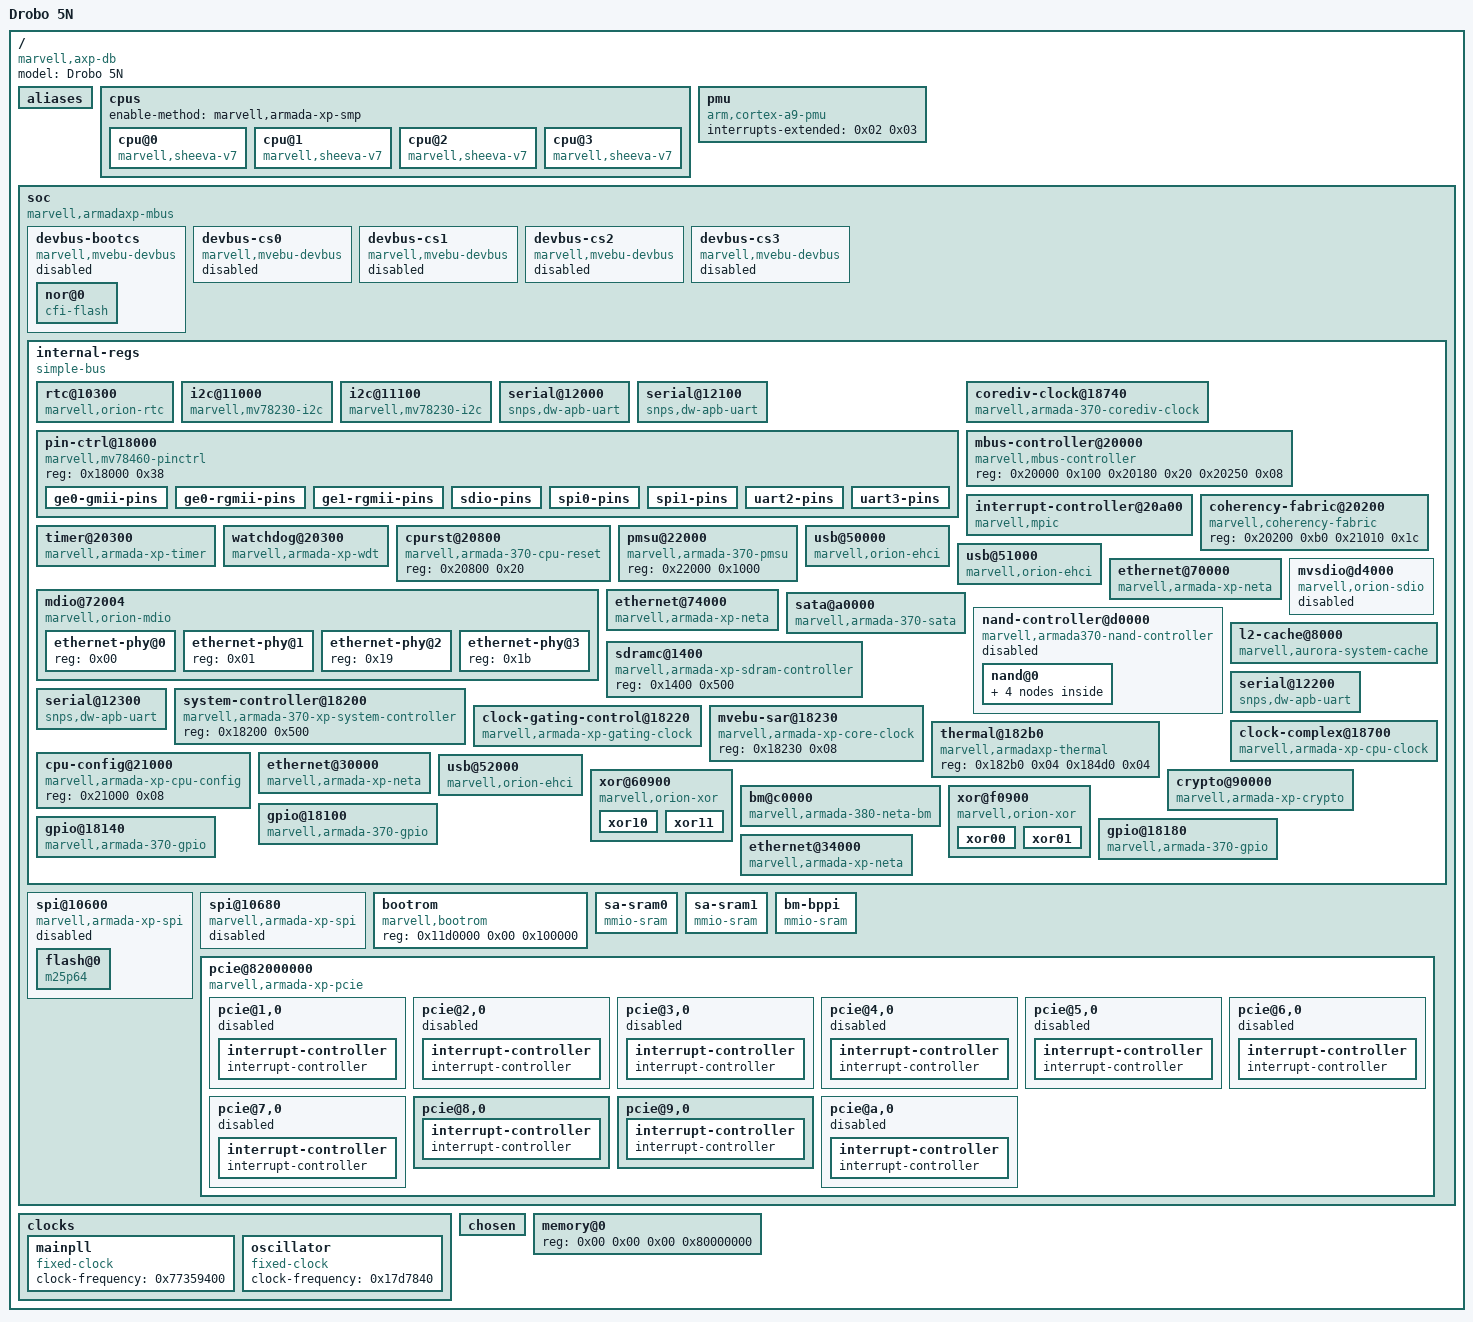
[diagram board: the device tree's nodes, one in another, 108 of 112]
/* Drobo 5N base device tree: mainline armada-xp-db with the register window at 0xd0000000,
   flash/SD/NAND off, only PCIe 8,0 and 9,0 on, both I2C buses on at 100 kHz.
   drobo5n-fixups.dtsi is applied on top by mkdrobodtb. */
/dts-v1/;

/ {
	model = "Drobo 5N";
	compatible = "marvell,axp-db", "marvell,armadaxp-mv78460", "marvell,armadaxp", "marvell,armada-370-xp";
	#address-cells = <0x02>;
	#size-cells = <0x02>;

	aliases {
		serial0 = "/soc/internal-regs/serial@12000";
		serial1 = "/soc/internal-regs/serial@12100";
		serial2 = "/soc/internal-regs/serial@12200";
		serial3 = "/soc/internal-regs/serial@12300";
		gpio0 = "/soc/internal-regs/gpio@18100";
		gpio1 = "/soc/internal-regs/gpio@18140";
		gpio2 = "/soc/internal-regs/gpio@18180";
	};

	cpus {
		#address-cells = <0x01>;
		#size-cells = <0x00>;
		enable-method = "marvell,armada-xp-smp";

		cpu@0 {
			compatible = "marvell,sheeva-v7";
			device_type = "cpu";
			reg = <0x00>;
			clocks = <0x01 0x00>;
			clock-latency = <0xf4240>;
		};

		cpu@1 {
			device_type = "cpu";
			compatible = "marvell,sheeva-v7";
			reg = <0x01>;
			clocks = <0x01 0x01>;
			clock-latency = <0xf4240>;
		};

		cpu@2 {
			device_type = "cpu";
			compatible = "marvell,sheeva-v7";
			reg = <0x02>;
			clocks = <0x01 0x02>;
			clock-latency = <0xf4240>;
		};

		cpu@3 {
			device_type = "cpu";
			compatible = "marvell,sheeva-v7";
			reg = <0x03>;
			clocks = <0x01 0x03>;
			clock-latency = <0xf4240>;
		};
	};

	pmu {
		compatible = "arm,cortex-a9-pmu";
		interrupts-extended = <0x02 0x03>;
	};

	soc {
		#address-cells = <0x02>;
		#size-cells = <0x01>;
		controller = <0x03>;
		interrupt-parent = <0x02>;
		pcie-mem-aperture = <0xf8000000 0x7e00000>;
		pcie-io-aperture = <0xffe00000 0x100000>;
		compatible = "marvell,armadaxp-mbus", "simple-bus";
		ranges = <0xf0010000 0x00 0x00 0xd0000000 0x100000 0x11d0000 0x00 0x00 0xfff00000 0x100000 0x12f0000 0x00 0x00 0xf0000000 0x1000000 0x9090000 0x00 0x00 0xf1100000 0x10000 0x9050000 0x00 0x00 0xf1110000 0x10000 0xc040000 0x00 0x00 0xf1200000 0x100000>;

		devbus-bootcs {
			compatible = "marvell,mvebu-devbus";
			reg = <0xf0010000 0x10400 0x08>;
			ranges = <0x00 0x12f0000 0x00 0xffffffff>;
			#address-cells = <0x01>;
			#size-cells = <0x01>;
			clocks = <0x04 0x00>;
			status = "disabled";
			devbus,bus-width = <0x10>;
			devbus,turn-off-ps = <0xea60>;
			devbus,badr-skew-ps = <0x00>;
			devbus,acc-first-ps = <0x1e460>;
			devbus,acc-next-ps = <0x3c8c0>;
			devbus,rd-setup-ps = <0x00>;
			devbus,rd-hold-ps = <0x00>;
			devbus,sync-enable = <0x00>;
			devbus,wr-high-ps = <0xea60>;
			devbus,wr-low-ps = <0xea60>;
			devbus,ale-wr-ps = <0xea60>;

			nor@0 {
				compatible = "cfi-flash";
				reg = <0x00 0x1000000>;
				bank-width = <0x02>;
			};
		};

		devbus-cs0 {
			compatible = "marvell,mvebu-devbus";
			reg = <0xf0010000 0x10408 0x08>;
			ranges = <0x00 0x13e0000 0x00 0xffffffff>;
			#address-cells = <0x01>;
			#size-cells = <0x01>;
			clocks = <0x04 0x00>;
			status = "disabled";
		};

		devbus-cs1 {
			compatible = "marvell,mvebu-devbus";
			reg = <0xf0010000 0x10410 0x08>;
			ranges = <0x00 0x13d0000 0x00 0xffffffff>;
			#address-cells = <0x01>;
			#size-cells = <0x01>;
			clocks = <0x04 0x00>;
			status = "disabled";
		};

		devbus-cs2 {
			compatible = "marvell,mvebu-devbus";
			reg = <0xf0010000 0x10418 0x08>;
			ranges = <0x00 0x13b0000 0x00 0xffffffff>;
			#address-cells = <0x01>;
			#size-cells = <0x01>;
			clocks = <0x04 0x00>;
			status = "disabled";
		};

		devbus-cs3 {
			compatible = "marvell,mvebu-devbus";
			reg = <0xf0010000 0x10420 0x08>;
			ranges = <0x00 0x1370000 0x00 0xffffffff>;
			#address-cells = <0x01>;
			#size-cells = <0x01>;
			clocks = <0x04 0x00>;
			status = "disabled";
		};

		internal-regs {
			compatible = "simple-bus";
			#address-cells = <0x01>;
			#size-cells = <0x01>;
			ranges = <0x00 0xf0010000 0x00 0x100000>;

			rtc@10300 {
				compatible = "marvell,orion-rtc";
				reg = <0x10300 0x20>;
				interrupts = <0x32>;
			};

			i2c@11000 {
				compatible = "marvell,mv78230-i2c", "marvell,mv64xxx-i2c";
				#address-cells = <0x01>;
				#size-cells = <0x00>;
				interrupts = <0x1f>;
				clocks = <0x04 0x00>;
				status = "okay";
				clock-frequency = <100000>;
				reg = <0x11000 0x100>;
			};

			i2c@11100 {
				compatible = "marvell,mv78230-i2c", "marvell,mv64xxx-i2c";
				#address-cells = <0x01>;
				#size-cells = <0x00>;
				interrupts = <0x20>;
				clocks = <0x04 0x00>;
				status = "okay";
				clock-frequency = <100000>;
				reg = <0x11100 0x100>;
			};

			serial@12000 {
				compatible = "snps,dw-apb-uart";
				reg = <0x12000 0x100>;
				reg-shift = <0x02>;
				interrupts = <0x29>;
				reg-io-width = <0x01>;
				clocks = <0x04 0x00>;
				status = "okay";
			};

			serial@12100 {
				compatible = "snps,dw-apb-uart";
				reg = <0x12100 0x100>;
				reg-shift = <0x02>;
				interrupts = <0x2a>;
				reg-io-width = <0x01>;
				clocks = <0x04 0x00>;
				status = "okay";
			};

			pin-ctrl@18000 {
				reg = <0x18000 0x38>;
				compatible = "marvell,mv78460-pinctrl";

				ge0-gmii-pins {
					marvell,pins = "mpp0", "mpp1", "mpp2", "mpp3", "mpp4", "mpp5", "mpp6", "mpp7", "mpp8", "mpp9", "mpp10", "mpp11", "mpp12", "mpp13", "mpp14", "mpp15", "mpp16", "mpp17", "mpp18", "mpp19", "mpp20", "mpp21", "mpp22", "mpp23";
					marvell,function = "ge0";
				};

				ge0-rgmii-pins {
					marvell,pins = "mpp0", "mpp1", "mpp2", "mpp3", "mpp4", "mpp5", "mpp6", "mpp7", "mpp8", "mpp9", "mpp10", "mpp11";
					marvell,function = "ge0";
				};

				ge1-rgmii-pins {
					marvell,pins = "mpp12", "mpp13", "mpp14", "mpp15", "mpp16", "mpp17", "mpp18", "mpp19", "mpp20", "mpp21", "mpp22", "mpp23";
					marvell,function = "ge1";
				};

				sdio-pins {
					marvell,pins = "mpp30", "mpp31", "mpp32", "mpp33", "mpp34", "mpp35";
					marvell,function = "sd0";
					phandle = <0x0c>;
				};

				spi0-pins {
					marvell,pins = "mpp36", "mpp37", "mpp38", "mpp39";
					marvell,function = "spi0";
					phandle = <0x14>;
				};

				spi1-pins {
					marvell,pins = "mpp13", "mpp14", "mpp16", "mpp17";
					marvell,function = "spi1";
					phandle = <0x15>;
				};

				uart2-pins {
					marvell,pins = "mpp42", "mpp43";
					marvell,function = "uart2";
					phandle = <0x0d>;
				};

				uart3-pins {
					marvell,pins = "mpp44", "mpp45";
					marvell,function = "uart3";
					phandle = <0x0e>;
				};
			};

			corediv-clock@18740 {
				compatible = "marvell,armada-370-corediv-clock";
				reg = <0x18740 0x0c>;
				#clock-cells = <0x01>;
				clocks = <0x05>;
				clock-output-names = "nand";
				phandle = <0x0b>;
			};

			mbus-controller@20000 {
				compatible = "marvell,mbus-controller";
				reg = <0x20000 0x100 0x20180 0x20 0x20250 0x08>;
				phandle = <0x03>;
			};

			interrupt-controller@20a00 {
				compatible = "marvell,mpic";
				#interrupt-cells = <0x01>;
				interrupt-controller;
				msi-controller;
				reg = <0x20a00 0x2d0 0x21070 0x58>;
				phandle = <0x02>;
			};

			coherency-fabric@20200 {
				compatible = "marvell,coherency-fabric";
				reg = <0x20200 0xb0 0x21010 0x1c>;
			};

			timer@20300 {
				reg = <0x20300 0x30 0x21040 0x30>;
				interrupts = <0x25 0x26 0x27 0x28 0x05 0x06>;
				compatible = "marvell,armada-xp-timer";
				clocks = <0x04 0x02 0x06>;
				clock-names = "nbclk", "fixed";
			};

			watchdog@20300 {
				reg = <0x20300 0x34 0x20704 0x04>;
				compatible = "marvell,armada-xp-wdt";
				clocks = <0x04 0x02 0x06>;
				clock-names = "nbclk", "fixed";
				interrupts = <0x5d 0x26>;
			};

			cpurst@20800 {
				compatible = "marvell,armada-370-cpu-reset";
				reg = <0x20800 0x20>;
			};

			pmsu@22000 {
				compatible = "marvell,armada-370-pmsu";
				reg = <0x22000 0x1000>;
			};

			usb@50000 {
				compatible = "marvell,orion-ehci";
				reg = <0x50000 0x500>;
				interrupts = <0x2d>;
				status = "okay";
				clocks = <0x07 0x12>;
			};

			usb@51000 {
				compatible = "marvell,orion-ehci";
				reg = <0x51000 0x500>;
				interrupts = <0x2e>;
				status = "okay";
				clocks = <0x07 0x13>;
			};

			ethernet@70000 {
				/* Put your board's MAC here (from U-Boot: printenv ethaddr) so DHCP gives a stable address:
				   local-mac-address = [00 1a 62 xx xx xx]; */
				reg = <0x70000 0x4000>;
				interrupts = <0x08>;
				clocks = <0x07 0x04>;
				status = "okay";
				compatible = "marvell,armada-xp-neta";
				phy = <0x08>;
				phy-mode = "rgmii-id";
				buffer-manager = <0x09>;
				bm,pool-long = <0x00>;
			};

			mdio@72004 {
				#address-cells = <0x01>;
				#size-cells = <0x00>;
				compatible = "marvell,orion-mdio";
				reg = <0x72004 0x04>;
				clocks = <0x07 0x04>;

				ethernet-phy@0 {
					reg = <0x00>;
					phandle = <0x08>;
				};

				ethernet-phy@1 {
					reg = <0x01>;
					phandle = <0x0a>;
				};

				ethernet-phy@2 {
					reg = <0x19>;
					phandle = <0x0f>;
				};

				ethernet-phy@3 {
					reg = <0x1b>;
					phandle = <0x13>;
				};
			};

			ethernet@74000 {
				reg = <0x74000 0x4000>;
				interrupts = <0x0a>;
				clocks = <0x07 0x03>;
				status = "okay";
				compatible = "marvell,armada-xp-neta";
				phy = <0x0a>;
				phy-mode = "rgmii-id";
				buffer-manager = <0x09>;
				bm,pool-long = <0x01>;
			};

			sata@a0000 {
				compatible = "marvell,armada-370-sata";
				reg = <0xa0000 0x5000>;
				interrupts = <0x37>;
				clocks = <0x07 0x0f 0x07 0x1e>;
				clock-names = "0", "1";
				status = "okay";
				nr-ports = <0x02>;
			};

			nand-controller@d0000 {
				compatible = "marvell,armada370-nand-controller";
				reg = <0xd0000 0x54>;
				#address-cells = <0x01>;
				#size-cells = <0x00>;
				interrupts = <0x71>;
				clocks = <0x0b 0x00>;
				status = "disabled";

				nand@0 {
					reg = <0x00>;
					label = "pxa3xx_nand-0";
					nand-rb = <0x00>;
					nand-on-flash-bbt;

					partitions {
						compatible = "fixed-partitions";
						#address-cells = <0x01>;
						#size-cells = <0x01>;

						partition@0 {
							label = "U-Boot";
							reg = <0x00 0x800000>;
						};

						partition@800000 {
							label = "Linux";
							reg = <0x800000 0x800000>;
						};

						partition@1000000 {
							label = "Filesystem";
							reg = <0x1000000 0x3f000000>;
						};
					};
				};
			};

			mvsdio@d4000 {
				compatible = "marvell,orion-sdio";
				reg = <0xd4000 0x200>;
				interrupts = <0x36>;
				clocks = <0x07 0x11>;
				bus-width = <0x04>;
				cap-sdio-irq;
				cap-sd-highspeed;
				cap-mmc-highspeed;
				status = "disabled";
				pinctrl-0 = <0x0c>;
				pinctrl-names = "default";
				broken-cd;
			};

			sdramc@1400 {
				compatible = "marvell,armada-xp-sdram-controller";
				reg = <0x1400 0x500>;
			};

			l2-cache@8000 {
				compatible = "marvell,aurora-system-cache";
				reg = <0x8000 0x1000>;
				cache-id-part = <0x100>;
				cache-level = <0x02>;
				cache-unified;
				wt-override;
			};

			serial@12200 {
				compatible = "snps,dw-apb-uart";
				pinctrl-0 = <0x0d>;
				pinctrl-names = "default";
				reg = <0x12200 0x100>;
				reg-shift = <0x02>;
				interrupts = <0x2b>;
				reg-io-width = <0x01>;
				clocks = <0x04 0x00>;
				status = "okay";
			};

			serial@12300 {
				compatible = "snps,dw-apb-uart";
				pinctrl-0 = <0x0e>;
				pinctrl-names = "default";
				reg = <0x12300 0x100>;
				reg-shift = <0x02>;
				interrupts = <0x2c>;
				reg-io-width = <0x01>;
				clocks = <0x04 0x00>;
				status = "okay";
			};

			system-controller@18200 {
				compatible = "marvell,armada-370-xp-system-controller";
				reg = <0x18200 0x500>;
			};

			clock-gating-control@18220 {
				compatible = "marvell,armada-xp-gating-clock";
				reg = <0x18220 0x04>;
				clocks = <0x04 0x00>;
				#clock-cells = <0x01>;
				phandle = <0x07>;
			};

			mvebu-sar@18230 {
				compatible = "marvell,armada-xp-core-clock";
				reg = <0x18230 0x08>;
				#clock-cells = <0x01>;
				phandle = <0x04>;
			};

			thermal@182b0 {
				compatible = "marvell,armadaxp-thermal";
				reg = <0x182b0 0x04 0x184d0 0x04>;
				status = "okay";
			};

			clock-complex@18700 {
				#clock-cells = <0x01>;
				compatible = "marvell,armada-xp-cpu-clock";
				reg = <0x18700 0x24 0x1c054 0x10>;
				clocks = <0x04 0x01>;
				phandle = <0x01>;
			};

			cpu-config@21000 {
				compatible = "marvell,armada-xp-cpu-config";
				reg = <0x21000 0x08>;
			};

			ethernet@30000 {
				compatible = "marvell,armada-xp-neta";
				reg = <0x30000 0x4000>;
				interrupts = <0x0c>;
				clocks = <0x07 0x02>;
				status = "okay";
				phy = <0x0f>;
				phy-mode = "sgmii";
				buffer-manager = <0x09>;
				bm,pool-long = <0x02>;
			};

			usb@52000 {
				compatible = "marvell,orion-ehci";
				reg = <0x52000 0x500>;
				interrupts = <0x2f>;
				clocks = <0x07 0x14>;
				status = "okay";
			};

			xor@60900 {
				compatible = "marvell,orion-xor";
				reg = <0x60900 0x100 0x60b00 0x100>;
				clocks = <0x07 0x16>;
				status = "okay";

				xor10 {
					interrupts = <0x33>;
					dmacap,memcpy;
					dmacap,xor;
				};

				xor11 {
					interrupts = <0x34>;
					dmacap,memcpy;
					dmacap,xor;
					dmacap,memset;
				};
			};

			crypto@90000 {
				compatible = "marvell,armada-xp-crypto";
				reg = <0x90000 0x10000>;
				reg-names = "regs";
				interrupts = <0x30 0x31>;
				clocks = <0x07 0x17 0x07 0x17>;
				clock-names = "cesa0", "cesa1";
				marvell,crypto-srams = <0x10 0x11>;
				marvell,crypto-sram-size = <0x800>;
			};

			bm@c0000 {
				compatible = "marvell,armada-380-neta-bm";
				reg = <0xc0000 0xac>;
				clocks = <0x07 0x0d>;
				internal-mem = <0x12>;
				status = "okay";
				phandle = <0x09>;
			};

			xor@f0900 {
				compatible = "marvell,orion-xor";
				reg = <0xf0900 0x100 0xf0b00 0x100>;
				clocks = <0x07 0x1c>;
				status = "okay";

				xor00 {
					interrupts = <0x5e>;
					dmacap,memcpy;
					dmacap,xor;
				};

				xor01 {
					interrupts = <0x5f>;
					dmacap,memcpy;
					dmacap,xor;
					dmacap,memset;
				};
			};

			gpio@18100 {
				compatible = "marvell,armada-370-gpio", "marvell,orion-gpio";
				reg = <0x18100 0x40 0x181c0 0x08>;
				reg-names = "gpio", "pwm";
				ngpios = <0x20>;
				gpio-controller;
				#gpio-cells = <0x02>;
				#pwm-cells = <0x02>;
				interrupt-controller;
				#interrupt-cells = <0x02>;
				interrupts = <0x52 0x53 0x54 0x55>;
				clocks = <0x04 0x00>;
			};

			gpio@18140 {
				compatible = "marvell,armada-370-gpio", "marvell,orion-gpio";
				reg = <0x18140 0x40 0x181c8 0x08>;
				reg-names = "gpio", "pwm";
				ngpios = <0x20>;
				gpio-controller;
				#gpio-cells = <0x02>;
				#pwm-cells = <0x02>;
				interrupt-controller;
				#interrupt-cells = <0x02>;
				interrupts = <0x57 0x58 0x59 0x5a>;
				clocks = <0x04 0x00>;
			};

			gpio@18180 {
				compatible = "marvell,armada-370-gpio", "marvell,orion-gpio";
				reg = <0x18180 0x40>;
				ngpios = <0x03>;
				gpio-controller;
				#gpio-cells = <0x02>;
				interrupt-controller;
				#interrupt-cells = <0x02>;
				interrupts = <0x5b>;
			};

			ethernet@34000 {
				compatible = "marvell,armada-xp-neta";
				reg = <0x34000 0x4000>;
				interrupts = <0x0e>;
				clocks = <0x07 0x01>;
				status = "okay";
				phy = <0x13>;
				phy-mode = "sgmii";
				buffer-manager = <0x09>;
				bm,pool-long = <0x03>;
			};
		};

		spi@10600 {
			reg = <0xf0010000 0x10600 0x28 0x11e0000 0x00 0xffffffff 0x15e0000 0x00 0xffffffff 0x19e0000 0x00 0xffffffff 0x1de0000 0x00 0xffffffff 0x11f0000 0x00 0xffffffff 0x15f0000 0x00 0xffffffff 0x19f0000 0x00 0xffffffff 0x1df0000 0x00 0xffffffff>;
			#address-cells = <0x01>;
			#size-cells = <0x00>;
			cell-index = <0x00>;
			interrupts = <0x1e>;
			clocks = <0x04 0x00>;
			status = "disabled";
			compatible = "marvell,armada-xp-spi", "marvell,orion-spi";
			pinctrl-0 = <0x14>;
			pinctrl-names = "default";

			flash@0 {
				#address-cells = <0x01>;
				#size-cells = <0x01>;
				compatible = "m25p64", "jedec,spi-nor";
				reg = <0x00>;
				spi-max-frequency = <0x1312d00>;
			};
		};

		spi@10680 {
			reg = <0xf0010000 0x10680 0x28 0x11a0000 0x00 0xffffffff 0x15a0000 0x00 0xffffffff 0x19a0000 0x00 0xffffffff 0x1da0000 0x00 0xffffffff 0x11b0000 0x00 0xffffffff 0x15b0000 0x00 0xffffffff 0x19b0000 0x00 0xffffffff 0x1db0000 0x00 0xffffffff>;
			#address-cells = <0x01>;
			#size-cells = <0x00>;
			cell-index = <0x01>;
			interrupts = <0x5c>;
			clocks = <0x04 0x00>;
			status = "disabled";
			compatible = "marvell,armada-xp-spi", "marvell,orion-spi";
			pinctrl-0 = <0x15>;
			pinctrl-names = "default";
		};

		bootrom {
			compatible = "marvell,bootrom";
			reg = <0x11d0000 0x00 0x100000>;
		};

		sa-sram0 {
			compatible = "mmio-sram";
			reg = <0x9090000 0x00 0x800>;
			clocks = <0x07 0x17>;
			#address-cells = <0x01>;
			#size-cells = <0x01>;
			ranges = <0x00 0x9090000 0x00 0x800>;
			phandle = <0x10>;
		};

		sa-sram1 {
			compatible = "mmio-sram";
			reg = <0x9050000 0x00 0x800>;
			clocks = <0x07 0x17>;
			#address-cells = <0x01>;
			#size-cells = <0x01>;
			ranges = <0x00 0x9050000 0x00 0x800>;
			phandle = <0x11>;
		};

		bm-bppi {
			compatible = "mmio-sram";
			reg = <0xc040000 0x00 0x100000>;
			ranges = <0x00 0xc040000 0x00 0x100000>;
			#address-cells = <0x01>;
			#size-cells = <0x01>;
			clocks = <0x07 0x0d>;
			no-memory-wc;
			status = "okay";
			phandle = <0x12>;
		};

		pcie@82000000 {
			compatible = "marvell,armada-xp-pcie";
			status = "okay";
			device_type = "pci";
			#address-cells = <0x03>;
			#size-cells = <0x02>;
			msi-parent = <0x02>;
			bus-range = <0x00 0xff>;
			ranges = <0x82000000 0x00 0x40000 0xf0010000 0x40000 0x00 0x2000 0x82000000 0x00 0x42000 0xf0010000 0x42000 0x00 0x2000 0x82000000 0x00 0x44000 0xf0010000 0x44000 0x00 0x2000 0x82000000 0x00 0x48000 0xf0010000 0x48000 0x00 0x2000 0x82000000 0x00 0x4c000 0xf0010000 0x4c000 0x00 0x2000 0x82000000 0x00 0x80000 0xf0010000 0x80000 0x00 0x2000 0x82000000 0x00 0x82000 0xf0010000 0x82000 0x00 0x2000 0x82000000 0x00 0x84000 0xf0010000 0x84000 0x00 0x2000 0x82000000 0x00 0x88000 0xf0010000 0x88000 0x00 0x2000 0x82000000 0x00 0x8c000 0xf0010000 0x8c000 0x00 0x2000 0x82000000 0x01 0x00 0x4e80000 0x00 0x01 0x00 0x81000000 0x01 0x00 0x4e00000 0x00 0x01 0x00 0x82000000 0x02 0x00 0x4d80000 0x00 0x01 0x00 0x81000000 0x02 0x00 0x4d00000 0x00 0x01 0x00 0x82000000 0x03 0x00 0x4b80000 0x00 0x01 0x00 0x81000000 0x03 0x00 0x4b00000 0x00 0x01 0x00 0x82000000 0x04 0x00 0x4780000 0x00 0x01 0x00 0x81000000 0x04 0x00 0x4700000 0x00 0x01 0x00 0x82000000 0x05 0x00 0x8e80000 0x00 0x01 0x00 0x81000000 0x05 0x00 0x8e00000 0x00 0x01 0x00 0x82000000 0x06 0x00 0x8d80000 0x00 0x01 0x00 0x81000000 0x06 0x00 0x8d00000 0x00 0x01 0x00 0x82000000 0x07 0x00 0x8b80000 0x00 0x01 0x00 0x81000000 0x07 0x00 0x8b00000 0x00 0x01 0x00 0x82000000 0x08 0x00 0x8780000 0x00 0x01 0x00 0x81000000 0x08 0x00 0x8700000 0x00 0x01 0x00 0x82000000 0x09 0x00 0x4f80000 0x00 0x01 0x00 0x81000000 0x09 0x00 0x4f00000 0x00 0x01 0x00 0x82000000 0x0a 0x00 0x8f80000 0x00 0x01 0x00 0x81000000 0x0a 0x00 0x8f00000 0x00 0x01 0x00>;

			pcie@1,0 {
				device_type = "pci";
				assigned-addresses = <0x82000800 0x00 0x40000 0x00 0x2000>;
				reg = <0x800 0x00 0x00 0x00 0x00>;
				#address-cells = <0x03>;
				#size-cells = <0x02>;
				interrupt-names = "intx";
				interrupts-extended = <0x02 0x3a>;
				#interrupt-cells = <0x01>;
				ranges = <0x82000000 0x00 0x00 0x82000000 0x01 0x00 0x01 0x00 0x81000000 0x00 0x00 0x81000000 0x01 0x00 0x01 0x00>;
				bus-range = <0x00 0xff>;
				interrupt-map-mask = <0x00 0x00 0x00 0x07>;
				interrupt-map = <0x00 0x00 0x00 0x01 0x16 0x00 0x00 0x00 0x00 0x02 0x16 0x01 0x00 0x00 0x00 0x03 0x16 0x02 0x00 0x00 0x00 0x04 0x16 0x03>;
				marvell,pcie-port = <0x00>;
				marvell,pcie-lane = <0x00>;
				clocks = <0x07 0x05>;
				status = "disabled";

				interrupt-controller {
					interrupt-controller;
					#interrupt-cells = <0x01>;
					phandle = <0x16>;
				};
			};

			pcie@2,0 {
				device_type = "pci";
				assigned-addresses = <0x82001000 0x00 0x44000 0x00 0x2000>;
				reg = <0x1000 0x00 0x00 0x00 0x00>;
				#address-cells = <0x03>;
				#size-cells = <0x02>;
				interrupt-names = "intx";
				interrupts-extended = <0x02 0x3b>;
				#interrupt-cells = <0x01>;
				ranges = <0x82000000 0x00 0x00 0x82000000 0x02 0x00 0x01 0x00 0x81000000 0x00 0x00 0x81000000 0x02 0x00 0x01 0x00>;
				bus-range = <0x00 0xff>;
				interrupt-map-mask = <0x00 0x00 0x00 0x07>;
				interrupt-map = <0x00 0x00 0x00 0x01 0x17 0x00 0x00 0x00 0x00 0x02 0x17 0x01 0x00 0x00 0x00 0x03 0x17 0x02 0x00 0x00 0x00 0x04 0x17 0x03>;
				marvell,pcie-port = <0x00>;
				marvell,pcie-lane = <0x01>;
				clocks = <0x07 0x06>;
				status = "disabled";

				interrupt-controller {
					interrupt-controller;
					#interrupt-cells = <0x01>;
					phandle = <0x17>;
				};
			};

			pcie@3,0 {
				device_type = "pci";
				assigned-addresses = <0x82001800 0x00 0x48000 0x00 0x2000>;
				reg = <0x1800 0x00 0x00 0x00 0x00>;
				#address-cells = <0x03>;
				#size-cells = <0x02>;
				interrupt-names = "intx";
				interrupts-extended = <0x02 0x3c>;
				#interrupt-cells = <0x01>;
				ranges = <0x82000000 0x00 0x00 0x82000000 0x03 0x00 0x01 0x00 0x81000000 0x00 0x00 0x81000000 0x03 0x00 0x01 0x00>;
				bus-range = <0x00 0xff>;
				interrupt-map-mask = <0x00 0x00 0x00 0x07>;
				interrupt-map = <0x00 0x00 0x00 0x01 0x18 0x00 0x00 0x00 0x00 0x02 0x18 0x01 0x00 0x00 0x00 0x03 0x18 0x02 0x00 0x00 0x00 0x04 0x18 0x03>;
				marvell,pcie-port = <0x00>;
				marvell,pcie-lane = <0x02>;
				clocks = <0x07 0x07>;
				status = "disabled";

				interrupt-controller {
					interrupt-controller;
					#interrupt-cells = <0x01>;
					phandle = <0x18>;
				};
			};

			pcie@4,0 {
				device_type = "pci";
				assigned-addresses = <0x82002000 0x00 0x4c000 0x00 0x2000>;
				reg = <0x2000 0x00 0x00 0x00 0x00>;
				#address-cells = <0x03>;
				#size-cells = <0x02>;
				interrupt-names = "intx";
				interrupts-extended = <0x02 0x3d>;
				#interrupt-cells = <0x01>;
				ranges = <0x82000000 0x00 0x00 0x82000000 0x04 0x00 0x01 0x00 0x81000000 0x00 0x00 0x81000000 0x04 0x00 0x01 0x00>;
				bus-range = <0x00 0xff>;
				interrupt-map-mask = <0x00 0x00 0x00 0x07>;
				interrupt-map = <0x00 0x00 0x00 0x01 0x19 0x00 0x00 0x00 0x00 0x02 0x19 0x01 0x00 0x00 0x00 0x03 0x19 0x02 0x00 0x00 0x00 0x04 0x19 0x03>;
				marvell,pcie-port = <0x00>;
				marvell,pcie-lane = <0x03>;
				clocks = <0x07 0x08>;
				status = "disabled";

				interrupt-controller {
					interrupt-controller;
					#interrupt-cells = <0x01>;
					phandle = <0x19>;
				};
			};

			pcie@5,0 {
				device_type = "pci";
				assigned-addresses = <0x82002800 0x00 0x80000 0x00 0x2000>;
				reg = <0x2800 0x00 0x00 0x00 0x00>;
				#address-cells = <0x03>;
				#size-cells = <0x02>;
				interrupt-names = "intx";
				interrupts-extended = <0x02 0x3e>;
				#interrupt-cells = <0x01>;
				ranges = <0x82000000 0x00 0x00 0x82000000 0x05 0x00 0x01 0x00 0x81000000 0x00 0x00 0x81000000 0x05 0x00 0x01 0x00>;
				bus-range = <0x00 0xff>;
				interrupt-map-mask = <0x00 0x00 0x00 0x07>;
				interrupt-map = <0x00 0x00 0x00 0x01 0x1a 0x00 0x00 0x00 0x00 0x02 0x1a 0x01 0x00 0x00 0x00 0x03 0x1a 0x02 0x00 0x00 0x00 0x04 0x1a 0x03>;
				marvell,pcie-port = <0x01>;
				marvell,pcie-lane = <0x00>;
				clocks = <0x07 0x09>;
				status = "disabled";

				interrupt-controller {
					interrupt-controller;
					#interrupt-cells = <0x01>;
					phandle = <0x1a>;
				};
			};

			pcie@6,0 {
				device_type = "pci";
				assigned-addresses = <0x82003000 0x00 0x84000 0x00 0x2000>;
				reg = <0x3000 0x00 0x00 0x00 0x00>;
				#address-cells = <0x03>;
				#size-cells = <0x02>;
				interrupt-names = "intx";
				interrupts-extended = <0x02 0x3f>;
				#interrupt-cells = <0x01>;
				ranges = <0x82000000 0x00 0x00 0x82000000 0x06 0x00 0x01 0x00 0x81000000 0x00 0x00 0x81000000 0x06 0x00 0x01 0x00>;
				bus-range = <0x00 0xff>;
				interrupt-map-mask = <0x00 0x00 0x00 0x07>;
				interrupt-map = <0x00 0x00 0x00 0x01 0x1b 0x00 0x00 0x00 0x00 0x02 0x1b 0x01 0x00 0x00 0x00 0x03 0x1b 0x02 0x00 0x00 0x00 0x04 0x1b 0x03>;
				marvell,pcie-port = <0x01>;
				marvell,pcie-lane = <0x01>;
				clocks = <0x07 0x0a>;
				status = "disabled";

				interrupt-controller {
					interrupt-controller;
					#interrupt-cells = <0x01>;
					phandle = <0x1b>;
				};
			};

			pcie@7,0 {
				device_type = "pci";
				assigned-addresses = <0x82003800 0x00 0x88000 0x00 0x2000>;
				reg = <0x3800 0x00 0x00 0x00 0x00>;
				#address-cells = <0x03>;
				#size-cells = <0x02>;
				interrupt-names = "intx";
				interrupts-extended = <0x02 0x40>;
				#interrupt-cells = <0x01>;
				ranges = <0x82000000 0x00 0x00 0x82000000 0x07 0x00 0x01 0x00 0x81000000 0x00 0x00 0x81000000 0x07 0x00 0x01 0x00>;
				bus-range = <0x00 0xff>;
				interrupt-map-mask = <0x00 0x00 0x00 0x07>;
				interrupt-map = <0x00 0x00 0x00 0x01 0x1c 0x00 0x00 0x00 0x00 0x02 0x1c 0x01 0x00 0x00 0x00 0x03 0x1c 0x02 0x00 0x00 0x00 0x04 0x1c 0x03>;
				marvell,pcie-port = <0x01>;
				marvell,pcie-lane = <0x02>;
				clocks = <0x07 0x0b>;
				status = "disabled";

				interrupt-controller {
					interrupt-controller;
					#interrupt-cells = <0x01>;
					phandle = <0x1c>;
				};
			};

			pcie@8,0 {
				device_type = "pci";
				assigned-addresses = <0x82004000 0x00 0x8c000 0x00 0x2000>;
				reg = <0x4000 0x00 0x00 0x00 0x00>;
				#address-cells = <0x03>;
				#size-cells = <0x02>;
				interrupt-names = "intx";
				interrupts-extended = <0x02 0x41>;
				#interrupt-cells = <0x01>;
				ranges = <0x82000000 0x00 0x00 0x82000000 0x08 0x00 0x01 0x00 0x81000000 0x00 0x00 0x81000000 0x08 0x00 0x01 0x00>;
				bus-range = <0x00 0xff>;
				interrupt-map-mask = <0x00 0x00 0x00 0x07>;
				interrupt-map = <0x00 0x00 0x00 0x01 0x1d 0x00 0x00 0x00 0x00 0x02 0x1d 0x01 0x00 0x00 0x00 0x03 0x1d 0x02 0x00 0x00 0x00 0x04 0x1d 0x03>;
				marvell,pcie-port = <0x01>;
				marvell,pcie-lane = <0x03>;
				clocks = <0x07 0x0c>;
				status = "okay";

				interrupt-controller {
					interrupt-controller;
					#interrupt-cells = <0x01>;
					phandle = <0x1d>;
				};
			};

			pcie@9,0 {
				device_type = "pci";
				assigned-addresses = <0x82004800 0x00 0x42000 0x00 0x2000>;
				reg = <0x4800 0x00 0x00 0x00 0x00>;
				#address-cells = <0x03>;
				#size-cells = <0x02>;
				interrupt-names = "intx";
				interrupts-extended = <0x02 0x63>;
				#interrupt-cells = <0x01>;
				ranges = <0x82000000 0x00 0x00 0x82000000 0x09 0x00 0x01 0x00 0x81000000 0x00 0x00 0x81000000 0x09 0x00 0x01 0x00>;
				bus-range = <0x00 0xff>;
				interrupt-map-mask = <0x00 0x00 0x00 0x07>;
				interrupt-map = <0x00 0x00 0x00 0x01 0x1e 0x00 0x00 0x00 0x00 0x02 0x1e 0x01 0x00 0x00 0x00 0x03 0x1e 0x02 0x00 0x00 0x00 0x04 0x1e 0x03>;
				marvell,pcie-port = <0x02>;
				marvell,pcie-lane = <0x00>;
				clocks = <0x07 0x1a>;
				status = "okay";

				interrupt-controller {
					interrupt-controller;
					#interrupt-cells = <0x01>;
					phandle = <0x1e>;
				};
			};

			pcie@a,0 {
				device_type = "pci";
				assigned-addresses = <0x82005000 0x00 0x82000 0x00 0x2000>;
				reg = <0x5000 0x00 0x00 0x00 0x00>;
				#address-cells = <0x03>;
				#size-cells = <0x02>;
				interrupt-names = "intx";
				interrupts-extended = <0x02 0x67>;
				#interrupt-cells = <0x01>;
				ranges = <0x82000000 0x00 0x00 0x82000000 0x0a 0x00 0x01 0x00 0x81000000 0x00 0x00 0x81000000 0x0a 0x00 0x01 0x00>;
				bus-range = <0x00 0xff>;
				interrupt-map-mask = <0x00 0x00 0x00 0x07>;
				interrupt-map = <0x00 0x00 0x00 0x01 0x1f 0x00 0x00 0x00 0x00 0x02 0x1f 0x01 0x00 0x00 0x00 0x03 0x1f 0x02 0x00 0x00 0x00 0x04 0x1f 0x03>;
				marvell,pcie-port = <0x03>;
				marvell,pcie-lane = <0x00>;
				clocks = <0x07 0x1b>;
				status = "disabled";

				interrupt-controller {
					interrupt-controller;
					#interrupt-cells = <0x01>;
					phandle = <0x1f>;
				};
			};
		};
	};

	clocks {

		mainpll {
			compatible = "fixed-clock";
			#clock-cells = <0x00>;
			clock-frequency = <0x77359400>;
			phandle = <0x05>;
		};

		oscillator {
			compatible = "fixed-clock";
			#clock-cells = <0x00>;
			clock-frequency = <0x17d7840>;
			phandle = <0x06>;
		};
	};

	chosen {
		stdout-path = "serial0:115200n8";
		bootargs = "console=ttyS0,115200 earlycon=uart8250,mmio32,0xd0012000 root=/dev/sda1 rootfstype=ext2 rootwait";
		linux,initrd-start = <0x04000000>;
		linux,initrd-end = <0x4000000>;  /* set per initrd by make-boot-files.py / mkdrobokernel */
	};

	memory@0 {
		device_type = "memory";
		reg = <0x00 0x00 0x00 0x80000000>;
	};
};
